AUTOSAR XML (schema 4-2-2)
package /ARPackage_5
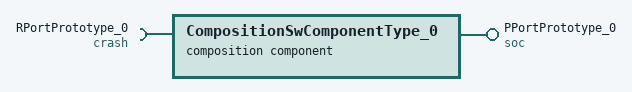
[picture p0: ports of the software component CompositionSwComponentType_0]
  composition sw component type CompositionSwComponentType_0
    provide port PPortPrototype_0: provided-interface=soc
    require port RPortPrototype_0: required-interface=crash
    4 x component:
      CPT_ComM: type=ComM
      CPT_swc: type=swc
      CPT_BswM: type=BswM
      CPT_EcuM: type=EcuM
    delegate CPT_swc.PPortPrototype_0 <-> outer port PPortPrototype_0
    delegate CPT_swc.RPortPrototype_0 <-> outer port RPortPrototype_0
